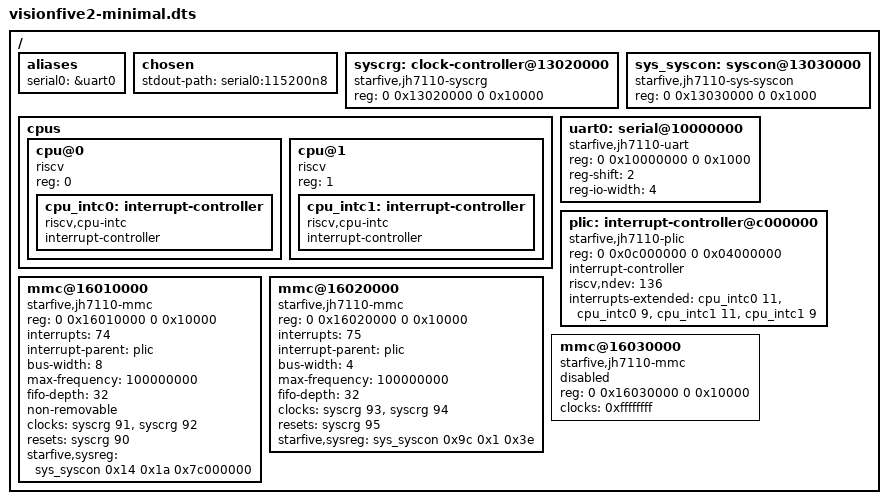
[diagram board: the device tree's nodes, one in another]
/dts-v1/;

/ {
    #address-cells = <2>;
    #size-cells = <2>;

    aliases { serial0 = &uart0; };
    chosen { stdout-path = "serial0:115200n8"; };

    syscrg: clock-controller@13020000 {
        compatible = "starfive,jh7110-syscrg";
        reg = <0 0x13020000 0 0x10000>;
        #clock-cells = <1>;
        #reset-cells = <1>;
    };
    sys_syscon: syscon@13030000 {
        compatible = "starfive,jh7110-sys-syscon", "syscon";
        reg = <0 0x13030000 0 0x1000>;
    };

    cpus {
        #address-cells = <1>;
        #size-cells = <0>;
        cpu@0 {
            device_type = "cpu";
            compatible = "riscv";
            reg = <0>;
            cpu_intc0: interrupt-controller {
                compatible = "riscv,cpu-intc";
                interrupt-controller;
                #interrupt-cells = <1>;
                phandle = <1>;
            };
        };
        cpu@1 {
            device_type = "cpu";
            compatible = "riscv";
            reg = <1>;
            cpu_intc1: interrupt-controller {
                compatible = "riscv,cpu-intc";
                interrupt-controller;
                #interrupt-cells = <1>;
                phandle = <2>;
            };
        };
    };
    uart0: serial@10000000 {
        compatible = "starfive,jh7110-uart", "snps,dw-apb-uart";
        reg = <0 0x10000000 0 0x1000>;
        reg-shift = <2>;
        reg-io-width = <4>;
    };
    plic: interrupt-controller@c000000 {
        compatible = "starfive,jh7110-plic", "sifive,plic-1.0.0";
        reg = <0 0x0c000000 0 0x04000000>;
        interrupt-controller;
        #interrupt-cells = <1>;
        riscv,ndev = <136>;
        interrupts-extended = <&cpu_intc0 11 &cpu_intc0 9
                               &cpu_intc1 11 &cpu_intc1 9>;
    };
    mmc@16010000 {
        compatible = "starfive,jh7110-mmc";
        reg = <0 0x16010000 0 0x10000>;
        interrupts = <74>;
        interrupt-parent = <&plic>;
        bus-width = <8>;
        max-frequency = <100000000>;
        fifo-depth = <32>;
        non-removable;
        clocks = <&syscrg 91>, <&syscrg 92>;
        clock-names = "biu", "ciu";
        resets = <&syscrg 90>;
        starfive,sysreg = <&sys_syscon 0x14 0x1a 0x7c000000>;
    };
    mmc@16020000 {
        compatible = "starfive,jh7110-mmc";
        reg = <0 0x16020000 0 0x10000>;
        interrupts = <75>;
        interrupt-parent = <&plic>;
        bus-width = <4>;
        max-frequency = <100000000>;
        fifo-depth = <32>;
        clocks = <&syscrg 93>, <&syscrg 94>;
        clock-names = "biu", "ciu";
        resets = <&syscrg 95>;
        starfive,sysreg = <&sys_syscon 0x9c 0x1 0x3e>;
    };
    mmc@16030000 {
        compatible = "starfive,jh7110-mmc";
        status = "disabled";
        reg = <0 0x16030000 0 0x10000>;
        /* Deliberately malformed resources: disabled nodes must be ignored. */
        clocks = <0xffffffff>;
    };
};
